# ATSAME54P20A device description
Architecture: CORTEX-M4; Family: SAMD; Series: SAME54
Registers are 32-bit, read-write, reset 0x0 unless marked. A register's access mark holds for its fields unless they carry their own. Offsets are from the block's base; [hi:lo] are bit positions; {n}, {i} and the like mark numbered series.

## DSU — Device Service Unit
Instances: DSU 0x41002000
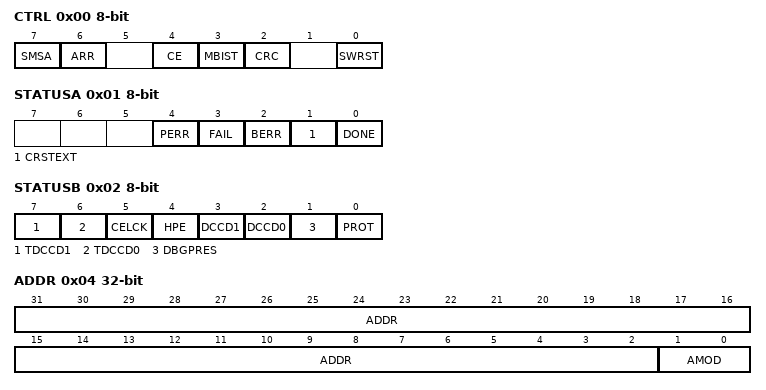
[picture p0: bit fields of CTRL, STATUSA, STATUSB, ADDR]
0x00 CTRL 8-bit wo — Control
  [7] SMSA — Start Memory Stream Access
  [6] ARR — Auxiliary Row Read
  [4] CE — Chip-Erase
  [3] MBIST — Memory built-in self-test
  [2] CRC — 32-bit Cyclic Redundancy Code
  [0] SWRST — Software Reset
0x01 STATUSA 8-bit
  [4] PERR — Protection Error
  [3] FAIL — Failure
  [2] BERR — Bus Error
  [1] CRSTEXT — CPU Reset Phase Extension
  [0] DONE
0x02 STATUSB 8-bit ro
  [7] TDCCD1 — Test Debug Communication Channel 1 Dirty
  [6] TDCCD0 — Test Debug Communication Channel 0 Dirty
  [5] CELCK — Chip Erase Locked
  [4] HPE — Hot-Plugging Enable
  [3] DCCD1 — Debug Communication Channel 1 Dirty
  [2] DCCD0 — Debug Communication Channel 0 Dirty
  [1] DBGPRES — Debugger Present
  [0] PROT — Protected
0x04 ADDR — Address
  [31:2] ADDR — Address
  [1:0] AMOD — Access Mode
0x08 LENGTH
  [31:2] LENGTH
0x0C DATA
{0x10+4i} DCC[{i}] (i=0..1) — Debug Communication Channel n
  [31:0] DATA
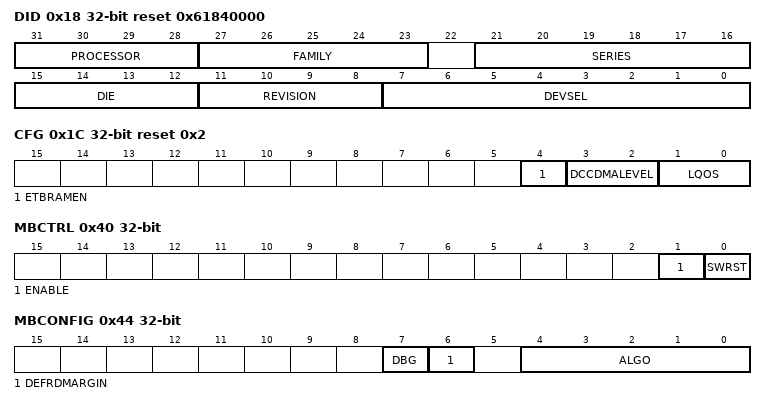
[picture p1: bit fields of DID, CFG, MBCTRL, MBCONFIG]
0x18 DID ro reset 0x61840000 — Device Identification
  [31:28] PROCESSOR
    1=CM0P (Cortex-M0+); 2=CM23 (Cortex-M23); 3=CM3 (Cortex-M3); 5=CM4 (Cortex-M4); 6=CM4F (Cortex-M4 with FPU); 7=CM33 (Cortex-M33)
  [27:23] FAMILY
    0=General purpose microcontroller; 1=PicoPower
  [21:16] SERIES
    0=Cortex-M0+ processor, basic feature set; 1=Cortex-M0+ processor, USB
  [15:12] DIE — Die Number
  [11:8] REVISION — Revision Number
  [7:0] DEVSEL — Device Select
0x1C CFG reset 0x2 — Configuration
  [4] ETBRAMEN — Trace Control
  [3:2] DCCDMALEVEL — DMA Trigger Level
    0=EMPTY (Trigger rises when DCC is empty); 1=FULL (Trigger rises when DCC is full)
  [1:0] LQOS — Latency Quality Of Service
0x40 MBCTRL — MBIST Control
  [1] ENABLE — MBIST Enable
  [0] SWRST — MBIST Software Reset
0x44 MBCONFIG — MBIST Configuration
  [7] DBG — Enable Debug Mode
  [6] DEFRDMARGIN — Force Default Read Margin
  [4:0] ALGO — MBIST Algorithm
    0=MEMCLEAR (Memory Clear (1n)); 1=VERIFY (Memory Verify (1n)); 2=CLEARVER (Memory Clear and Verify (2n)); 3=ADDR_DEC (Address Decoder (2n)); 4=MARCH_LR (March LR (14n)); 5=MARCH_SR (March SR (14n)); 6=MARCH_SS (March SS (22n)); 8=CRC_UP (CRC increasing address (1n)); 9=CRC_DOWN (CRC decreasing address (1n))
0x48 MBWORD — MBIST Background Word
  [31:0] DATA
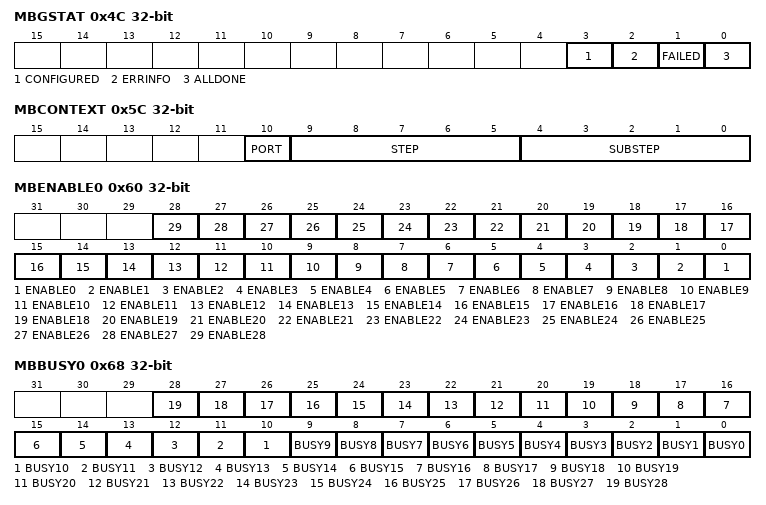
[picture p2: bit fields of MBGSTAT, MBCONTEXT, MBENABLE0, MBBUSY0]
0x4C MBGSTAT — MBIST Global Status
  [3] CONFIGURED — MBIST Configuration Sent
  [2] ERRINFO — MBIST Error Info Present
  [1] FAILED — MBIST Failed
  [0] ALLDONE — MBIST Completed
0x50 MBDFAIL ro — MBIST Fail Data
  [31:0] DATA — Error Data Read
0x54 MBDEXP ro — MBIST Expected Data
  [31:0] DATA — Expected Data
0x58 MBAFAIL ro — MBIST Fail Address
  [13:0] ADDR — Error Address
0x5C MBCONTEXT ro — MBIST Fail Context
  [10] PORT — DPRAM Port Index
  [9:5] STEP — Algorithm Step
    2=DOWN_R0W1; 3=UP_R1W0R0W1; 4=UP_R1W0; 5=UP_R0W1R1W0; 6=UP_R0; 7=UP_R0R0W0R0W1; 8=UP_R1R1W1R1W0; 9=DOWN_R0R0W0R0W1; 10=DOWN_R1R1W1R1W0; 12=UP_R0R0; 14=DOWN_R1W0R0W1; 15=DOWN_R1R1
  [4:0] SUBSTEP — Algorithm Sub-step
    1=R0_1; 3=R1_1; 5=R0_2; 7=R1_2; 9=R0_3; 11=R1_3
0x60 MBENABLE0 — MBIST Memory Enable 0
  [n] ENABLE{n} (n=0..28) — Memory {n} MBIST Enable
0x68 MBBUSY0 ro — MBIST Memory Busy 0
  [n] BUSY{n} (n=0..28) — Memory {n} BIST Busy
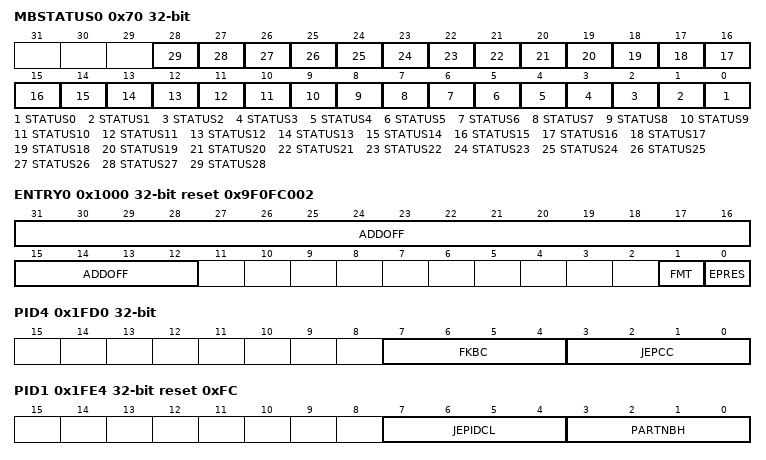
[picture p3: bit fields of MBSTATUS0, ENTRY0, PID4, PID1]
0x70 MBSTATUS0 — MBIST Memory Status 0
  [n] STATUS{n} (n=0..28) — Memory {n} MBIST Status
{0xF0+4i} DCFG[{i}] (i=0..1) — Device Configuration
0x1000 ENTRY0 ro reset 0x9F0FC002 — CoreSight ROM Table Entry 0
  [31:12] ADDOFF — Address Offset
  [1] FMT — Format
  [0] EPRES — Entry Present
0x1004 ENTRY1 ro — CoreSight ROM Table Entry 1
0x1008 END ro — CoreSight ROM Table End
  [31:0] END — End Marker
0x1FCC MEMTYPE ro — CoreSight ROM Table Memory Type
  [0] SMEMP — System Memory Present
0x1FD0 PID4 ro — Peripheral Identification 4
  [7:4] FKBC — 4KB count
  [3:0] JEPCC — JEP-106 Continuation Code
{0x1FC0+4i} PID{i} ro (i=5..7) — Peripheral Identification {i}
0x1FE0 PID0 ro reset 0xD0 — Peripheral Identification 0
  [7:0] PARTNBL — Part Number Low
0x1FE4 PID1 ro reset 0xFC — Peripheral Identification 1
  [7:4] JEPIDCL — Low part of the JEP-106 Identity Code
  [3:0] PARTNBH — Part Number High
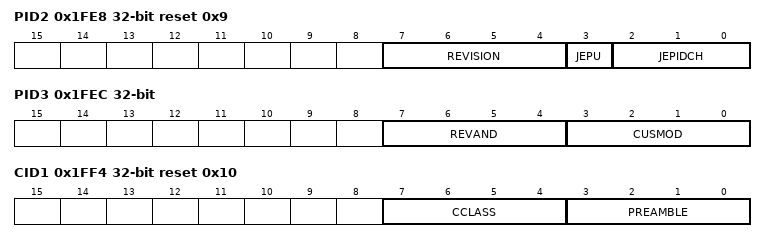
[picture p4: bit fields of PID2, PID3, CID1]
0x1FE8 PID2 ro reset 0x9 — Peripheral Identification 2
  [7:4] REVISION — Revision Number
  [3] JEPU — JEP-106 Identity Code is used
  [2:0] JEPIDCH — JEP-106 Identity Code High
0x1FEC PID3 ro — Peripheral Identification 3
  [7:4] REVAND — Revision Number
  [3:0] CUSMOD — ARM CUSMOD
0x1FF0 CID0 ro reset 0xD — Component Identification 0
  [7:0] PREAMBLEB0 — Preamble Byte 0
0x1FF4 CID1 ro reset 0x10 — Component Identification 1
  [7:4] CCLASS — Component Class
  [3:0] PREAMBLE
0x1FF8 CID2 ro reset 0x5 — Component Identification 2
  [7:0] PREAMBLEB2 — Preamble Byte 2
0x1FFC CID3 ro reset 0xB1 — Component Identification 3
  [7:0] PREAMBLEB3 — Preamble Byte 3
